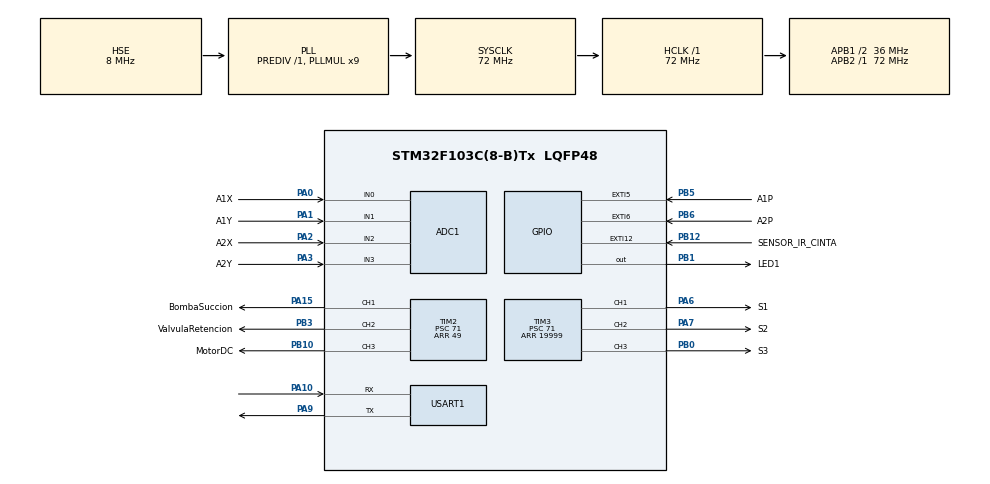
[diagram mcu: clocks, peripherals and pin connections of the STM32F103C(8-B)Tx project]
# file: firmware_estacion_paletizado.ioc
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ADC1.Channel-0\#ChannelRegularConversion=ADC_CHANNEL_0
ADC1.Channel-1\#ChannelRegularConversion=ADC_CHANNEL_1
ADC1.Channel-2\#ChannelRegularConversion=ADC_CHANNEL_2
ADC1.Channel-3\#ChannelRegularConversion=ADC_CHANNEL_3
ADC1.ContinuousConvMode=ENABLE
ADC1.NbrOfConversion=4
ADC1.NbrOfConversionFlag=1
ADC1.Rank-0\#ChannelRegularConversion=1
ADC1.Rank-1\#ChannelRegularConversion=2
ADC1.Rank-2\#ChannelRegularConversion=3
ADC1.Rank-3\#ChannelRegularConversion=4
ADC1.SamplingTime-0\#ChannelRegularConversion=ADC_SAMPLETIME_239CYCLES_5
ADC1.SamplingTime-1\#ChannelRegularConversion=ADC_SAMPLETIME_239CYCLES_5
ADC1.SamplingTime-2\#ChannelRegularConversion=ADC_SAMPLETIME_239CYCLES_5
ADC1.SamplingTime-3\#ChannelRegularConversion=ADC_SAMPLETIME_239CYCLES_5
ADC1.master=1
Dma.ADC1.0.Direction=DMA_PERIPH_TO_MEMORY
Dma.ADC1.0.Instance=DMA1_Channel1
Dma.ADC1.0.MemDataAlignment=DMA_MDATAALIGN_WORD
Dma.ADC1.0.MemInc=DMA_MINC_ENABLE
Dma.ADC1.0.Mode=DMA_CIRCULAR
Dma.ADC1.0.PeriphDataAlignment=DMA_PDATAALIGN_WORD
Dma.ADC1.0.PeriphInc=DMA_PINC_DISABLE
Dma.ADC1.0.Priority=DMA_PRIORITY_LOW
Dma.Request0=ADC1
Dma.Request1=USART1_TX
Dma.USART1_TX.1.Direction=DMA_MEMORY_TO_PERIPH
Dma.USART1_TX.1.Instance=DMA1_Channel4
Dma.USART1_TX.1.MemDataAlignment=DMA_MDATAALIGN_BYTE
Dma.USART1_TX.1.MemInc=DMA_MINC_ENABLE
Dma.USART1_TX.1.Mode=DMA_NORMAL
Dma.USART1_TX.1.PeriphDataAlignment=DMA_PDATAALIGN_BYTE
Dma.USART1_TX.1.PeriphInc=DMA_PINC_DISABLE
Dma.USART1_TX.1.Priority=DMA_PRIORITY_LOW
Mcu.Family=STM32F1
Mcu.Name=STM32F103C(8-B)Tx
Mcu.Package=LQFP48
NVIC.DMA1_Channel1_IRQn=true\:6\:0\:true\:true\:true\:1\:false\:true\:true
NVIC.DMA1_Channel4_IRQn=true\:5\:0\:true\:false\:true\:false\:true\:true
NVIC.EXTI15_10_IRQn=true\:6\:0\:true\:false\:true\:true\:true\:true
NVIC.EXTI9_5_IRQn=true\:14\:0\:true\:false\:true\:true\:true\:true
NVIC.PriorityGroup=NVIC_PRIORITYGROUP_4
NVIC.TIM3_IRQn=true\:1\:0\:true\:true\:true\:2\:true\:true\:true
NVIC.USART1_IRQn=true\:2\:0\:true\:true\:true\:3\:false\:true\:true
PA0-WKUP.GPIO_Label=A1X
PA0-WKUP.Signal=ADCx_IN0
PA1.GPIO_Label=A1Y
PA1.Signal=ADCx_IN1
PA10.Mode=Asynchronous
PA10.Signal=USART1_RX
PA13.Mode=Serial_Wire
PA13.Signal=SYS_JTMS-SWDIO
PA14.Mode=Serial_Wire
PA14.Signal=SYS_JTCK-SWCLK
PA15.GPIO_Label=BombaSuccion
PA15.GPIO_Speed=GPIO_SPEED_FREQ_HIGH
PA15.Signal=S_TIM2_CH1_ETR
PA2.GPIO_Label=A2X
PA2.Signal=ADCx_IN2
PA3.GPIO_Label=A2Y
PA3.Signal=ADCx_IN3
PA6.GPIO_Label=S1
PA6.Signal=S_TIM3_CH1
PA7.GPIO_Label=S2
PA7.Signal=S_TIM3_CH2
PA9.Mode=Asynchronous
PA9.Signal=USART1_TX
PB0.GPIO_Label=S3
PB0.Signal=S_TIM3_CH3
PB1.GPIO_Label=LED1
PB1.Signal=GPIO_Output
PB10.GPIO_Label=MotorDC
PB10.GPIO_Speed=GPIO_SPEED_FREQ_HIGH
PB10.Signal=S_TIM2_CH3
PB12.GPIO_Label=SENSOR_IR_CINTA
PB12.GPIO_ModeDefaultEXTI=GPIO_MODE_IT_RISING_FALLING
PB12.GPIO_PuPd=GPIO_PULLUP
PB12.Signal=GPXTI12
PB3.GPIO_Label=ValvulaRetencion
PB3.GPIO_Speed=GPIO_SPEED_FREQ_HIGH
PB3.Signal=S_TIM2_CH2
PB5.GPIO_Label=A1P
PB5.GPIO_ModeDefaultEXTI=GPIO_MODE_IT_FALLING
PB5.GPIO_PuPd=GPIO_PULLUP
PB5.Signal=GPXTI5
PB6.GPIO_Label=A2P
PB6.GPIO_ModeDefaultEXTI=GPIO_MODE_IT_FALLING
PB6.GPIO_PuPd=GPIO_PULLUP
PB6.Signal=GPXTI6
PD0-OSC_IN.Mode=HSE-External-Oscillator
PD0-OSC_IN.Signal=RCC_OSC_IN
PD1-OSC_OUT.Mode=HSE-External-Oscillator
PD1-OSC_OUT.Signal=RCC_OSC_OUT
ProjectManager.HeapSize=0x200
ProjectManager.StackSize=0x400
ProjectManager.TargetToolchain=STM32CubeIDE
RCC.ADCPresc=RCC_ADCPCLK2_DIV6
RCC.AHBFreq_Value=72000000
RCC.APB1CLKDivider=RCC_HCLK_DIV2
RCC.APB1Freq_Value=36000000
RCC.APB1TimFreq_Value=72000000
RCC.APB2Freq_Value=72000000
RCC.APB2TimFreq_Value=72000000
RCC.HCLKFreq_Value=72000000
RCC.PLLMUL=RCC_PLL_MUL9
RCC.PLLSourceVirtual=RCC_PLLSOURCE_HSE
RCC.SYSCLKFreq_VALUE=72000000
RCC.SYSCLKSource=RCC_SYSCLKSOURCE_PLLCLK
RCC.USBFreq_Value=72000000
SH.ADCx_IN0.0=ADC1_IN0,IN0
SH.ADCx_IN1.0=ADC1_IN1,IN1
SH.ADCx_IN2.0=ADC1_IN2,IN2
SH.ADCx_IN3.0=ADC1_IN3,IN3
SH.S_TIM2_CH1_ETR.0=TIM2_CH1,PWM Generation1 CH1
SH.S_TIM2_CH2.0=TIM2_CH2,PWM Generation2 CH2
SH.S_TIM2_CH3.0=TIM2_CH3,PWM Generation3 CH3
SH.S_TIM3_CH1.0=TIM3_CH1,PWM Generation1 CH1
SH.S_TIM3_CH2.0=TIM3_CH2,PWM Generation2 CH2
SH.S_TIM3_CH3.0=TIM3_CH3,PWM Generation3 CH3
TIM2.Channel-PWM\ Generation1\ CH1=TIM_CHANNEL_1
TIM2.Channel-PWM\ Generation2\ CH2=TIM_CHANNEL_2
TIM2.Channel-PWM\ Generation3\ CH3=TIM_CHANNEL_3
TIM2.Period=49
TIM2.Prescaler=71
TIM3.AutoReloadPreload=TIM_AUTORELOAD_PRELOAD_DISABLE
TIM3.Channel-PWM\ Generation1\ CH1=TIM_CHANNEL_1
TIM3.Channel-PWM\ Generation2\ CH2=TIM_CHANNEL_2
TIM3.Channel-PWM\ Generation3\ CH3=TIM_CHANNEL_3
TIM3.Period=19999
TIM3.Prescaler=71
TIM3.Pulse-PWM\ Generation1\ CH1=1500
TIM3.Pulse-PWM\ Generation2\ CH2=1500
TIM3.Pulse-PWM\ Generation3\ CH3=1500
USART1.VirtualMode=VM_ASYNC
VP_TIM2_VS_ClockSourceINT.Mode=Internal
VP_TIM3_VS_ClockSourceINT.Mode=Internal
board=custom

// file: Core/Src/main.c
/* USER CODE BEGIN Header */
/**
  ******************************************************************************
  * @file           : main.c
  * @brief          : Main program body
  ******************************************************************************
  * @attention
  *
  * Copyright (c) 2026 STMicroelectronics.
  * All rights reserved.
  *
  * This software is licensed under terms that can be found in the LICENSE file
  * in the root directory of this software component.
  * If no LICENSE file comes with this software, it is provided AS-IS.
  *
  ******************************************************************************
  */
/* USER CODE END Header */
#include "main.h"

/* USER CODE BEGIN Includes */
#include "main_cpp.hpp"
/* USER CODE END Includes */

ADC_HandleTypeDef hadc1;
DMA_HandleTypeDef hdma_adc1;

TIM_HandleTypeDef htim2;
TIM_HandleTypeDef htim3;

UART_HandleTypeDef huart1;
DMA_HandleTypeDef hdma_usart1_tx;

void SystemClock_Config(void);
static void MX_GPIO_Init(void);
static void MX_DMA_Init(void);
static void MX_ADC1_Init(void);
static void MX_TIM3_Init(void);
static void MX_USART1_UART_Init(void);
static void MX_TIM2_Init(void);
static void MX_NVIC_Init(void);

int main(void)
{

  /* MCU Configuration--------------------------------------------------------*/

  /* Reset of all peripherals, Initializes the Flash interface and the Systick. */
  HAL_Init();

  /* Configure the system clock */
  SystemClock_Config();

  /* Initialize all configured peripherals */
  MX_GPIO_Init();
  MX_DMA_Init();
  MX_ADC1_Init();
  MX_TIM3_Init();
  MX_USART1_UART_Init();
  MX_TIM2_Init();

  /* Initialize interrupts */
  MX_NVIC_Init();
  /* USER CODE BEGIN 2 */
  Cpp_Main_Init();
  /* USER CODE END 2 */

  /* Infinite loop */
  while (1)
  {

    /* USER CODE BEGIN 3 */
	  Cpp_Main_Loop();
  }
  /* USER CODE END 3 */
}

void SystemClock_Config(void)
{
  RCC_OscInitTypeDef RCC_OscInitStruct = {0};
  RCC_ClkInitTypeDef RCC_ClkInitStruct = {0};
  RCC_PeriphCLKInitTypeDef PeriphClkInit = {0};

  /** Initializes the RCC Oscillators according to the specified parameters
  * in the RCC_OscInitTypeDef structure.
  */
  RCC_OscInitStruct.OscillatorType = RCC_OSCILLATORTYPE_HSE;
  RCC_OscInitStruct.HSEState = RCC_HSE_ON;
  RCC_OscInitStruct.HSEPredivValue = RCC_HSE_PREDIV_DIV1;
  RCC_OscInitStruct.HSIState = RCC_HSI_ON;
  RCC_OscInitStruct.PLL.PLLState = RCC_PLL_ON;
  RCC_OscInitStruct.PLL.PLLSource = RCC_PLLSOURCE_HSE;
  RCC_OscInitStruct.PLL.PLLMUL = RCC_PLL_MUL9;
  if (HAL_RCC_OscConfig(&RCC_OscInitStruct) != HAL_OK)
  {
    Error_Handler();
  }

  /** Initializes the CPU, AHB and APB buses clocks
  */
  RCC_ClkInitStruct.ClockType = RCC_CLOCKTYPE_HCLK|RCC_CLOCKTYPE_SYSCLK
                              |RCC_CLOCKTYPE_PCLK1|RCC_CLOCKTYPE_PCLK2;
  RCC_ClkInitStruct.SYSCLKSource = RCC_SYSCLKSOURCE_PLLCLK;
  RCC_ClkInitStruct.AHBCLKDivider = RCC_SYSCLK_DIV1;
  RCC_ClkInitStruct.APB1CLKDivider = RCC_HCLK_DIV2;
  RCC_ClkInitStruct.APB2CLKDivider = RCC_HCLK_DIV1;

  if (HAL_RCC_ClockConfig(&RCC_ClkInitStruct, FLASH_LATENCY_2) != HAL_OK)
  {
    Error_Handler();
  }
  PeriphClkInit.PeriphClockSelection = RCC_PERIPHCLK_ADC;
  PeriphClkInit.AdcClockSelection = RCC_ADCPCLK2_DIV6;
  if (HAL_RCCEx_PeriphCLKConfig(&PeriphClkInit) != HAL_OK)
  {
    Error_Handler();
  }
}

/**
  * @brief NVIC Configuration.
  * @retval None
  */
static void MX_NVIC_Init(void)
{
  /* DMA1_Channel1_IRQn interrupt configuration */
  HAL_NVIC_SetPriority(DMA1_Channel1_IRQn, 6, 0);
  HAL_NVIC_EnableIRQ(DMA1_Channel1_IRQn);
  /* TIM3_IRQn interrupt configuration */
  HAL_NVIC_SetPriority(TIM3_IRQn, 1, 0);
  HAL_NVIC_EnableIRQ(TIM3_IRQn);
  /* USART1_IRQn interrupt configuration */
  HAL_NVIC_SetPriority(USART1_IRQn, 2, 0);
  HAL_NVIC_EnableIRQ(USART1_IRQn);
}

static void MX_ADC1_Init(void)
{

  ADC_ChannelConfTypeDef sConfig = {0};

  /** Common config
  */
  hadc1.Instance = ADC1;
  hadc1.Init.ScanConvMode = ADC_SCAN_ENABLE;
  hadc1.Init.ContinuousConvMode = ENABLE;
  hadc1.Init.DiscontinuousConvMode = DISABLE;
  hadc1.Init.ExternalTrigConv = ADC_SOFTWARE_START;
  hadc1.Init.DataAlign = ADC_DATAALIGN_RIGHT;
  hadc1.Init.NbrOfConversion = 4;
  if (HAL_ADC_Init(&hadc1) != HAL_OK)
  {
    Error_Handler();
  }

  /** Configure Regular Channel
  */
  sConfig.Channel = ADC_CHANNEL_0;
  sConfig.Rank = ADC_REGULAR_RANK_1;
  sConfig.SamplingTime = ADC_SAMPLETIME_239CYCLES_5;
  if (HAL_ADC_ConfigChannel(&hadc1, &sConfig) != HAL_OK)
  {
    Error_Handler();
  }

  /** Configure Regular Channel
  */
  sConfig.Channel = ADC_CHANNEL_1;
  sConfig.Rank = ADC_REGULAR_RANK_2;
  if (HAL_ADC_ConfigChannel(&hadc1, &sConfig) != HAL_OK)
  {
    Error_Handler();
  }

  /** Configure Regular Channel
  */
  sConfig.Channel = ADC_CHANNEL_2;
  sConfig.Rank = ADC_REGULAR_RANK_3;
  if (HAL_ADC_ConfigChannel(&hadc1, &sConfig) != HAL_OK)
  {
    Error_Handler();
  }

  /** Configure Regular Channel
  */
  sConfig.Channel = ADC_CHANNEL_3;
  sConfig.Rank = ADC_REGULAR_RANK_4;
  if (HAL_ADC_ConfigChannel(&hadc1, &sConfig) != HAL_OK)
  {
    Error_Handler();
  }

}

static void MX_TIM2_Init(void)
{

  TIM_ClockConfigTypeDef sClockSourceConfig = {0};
  TIM_MasterConfigTypeDef sMasterConfig = {0};
  TIM_OC_InitTypeDef sConfigOC = {0};

  htim2.Instance = TIM2;
  htim2.Init.Prescaler = 71;
  htim2.Init.CounterMode = TIM_COUNTERMODE_UP;
  htim2.Init.Period = 49;
  htim2.Init.ClockDivision = TIM_CLOCKDIVISION_DIV1;
  htim2.Init.AutoReloadPreload = TIM_AUTORELOAD_PRELOAD_DISABLE;
  if (HAL_TIM_Base_Init(&htim2) != HAL_OK)
  {
    Error_Handler();
  }
  sClockSourceConfig.ClockSource = TIM_CLOCKSOURCE_INTERNAL;
  if (HAL_TIM_ConfigClockSource(&htim2, &sClockSourceConfig) != HAL_OK)
  {
    Error_Handler();
  }
  if (HAL_TIM_PWM_Init(&htim2) != HAL_OK)
  {
    Error_Handler();
  }
  sMasterConfig.MasterOutputTrigger = TIM_TRGO_RESET;
  sMasterConfig.MasterSlaveMode = TIM_MASTERSLAVEMODE_DISABLE;
  if (HAL_TIMEx_MasterConfigSynchronization(&htim2, &sMasterConfig) != HAL_OK)
  {
    Error_Handler();
  }
  sConfigOC.OCMode = TIM_OCMODE_PWM1;
  sConfigOC.Pulse = 0;
  sConfigOC.OCPolarity = TIM_OCPOLARITY_HIGH;
  sConfigOC.OCFastMode = TIM_OCFAST_DISABLE;
  if (HAL_TIM_PWM_ConfigChannel(&htim2, &sConfigOC, TIM_CHANNEL_1) != HAL_OK)
  {
    Error_Handler();
  }
  if (HAL_TIM_PWM_ConfigChannel(&htim2, &sConfigOC, TIM_CHANNEL_2) != HAL_OK)
  {
    Error_Handler();
  }
  if (HAL_TIM_PWM_ConfigChannel(&htim2, &sConfigOC, TIM_CHANNEL_3) != HAL_OK)
  {
    Error_Handler();
  }
  HAL_TIM_MspPostInit(&htim2);

}

static void MX_TIM3_Init(void)
{

  TIM_ClockConfigTypeDef sClockSourceConfig = {0};
  TIM_MasterConfigTypeDef sMasterConfig = {0};
  TIM_OC_InitTypeDef sConfigOC = {0};

  htim3.Instance = TIM3;
  htim3.Init.Prescaler = 71;
  htim3.Init.CounterMode = TIM_COUNTERMODE_UP;
  htim3.Init.Period = 19999;
  htim3.Init.ClockDivision = TIM_CLOCKDIVISION_DIV1;
  htim3.Init.AutoReloadPreload = TIM_AUTORELOAD_PRELOAD_DISABLE;
  if (HAL_TIM_Base_Init(&htim3) != HAL_OK)
  {
    Error_Handler();
  }
  sClockSourceConfig.ClockSource = TIM_CLOCKSOURCE_INTERNAL;
  if (HAL_TIM_ConfigClockSource(&htim3, &sClockSourceConfig) != HAL_OK)
  {
    Error_Handler();
  }
  if (HAL_TIM_PWM_Init(&htim3) != HAL_OK)
  {
    Error_Handler();
  }
  sMasterConfig.MasterOutputTrigger = TIM_TRGO_RESET;
  sMasterConfig.MasterSlaveMode = TIM_MASTERSLAVEMODE_DISABLE;
  if (HAL_TIMEx_MasterConfigSynchronization(&htim3, &sMasterConfig) != HAL_OK)
  {
    Error_Handler();
  }
  sConfigOC.OCMode = TIM_OCMODE_PWM1;
  sConfigOC.Pulse = 1500;
  sConfigOC.OCPolarity = TIM_OCPOLARITY_HIGH;
  sConfigOC.OCFastMode = TIM_OCFAST_DISABLE;
  if (HAL_TIM_PWM_ConfigChannel(&htim3, &sConfigOC, TIM_CHANNEL_1) != HAL_OK)
  {
    Error_Handler();
  }
  if (HAL_TIM_PWM_ConfigChannel(&htim3, &sConfigOC, TIM_CHANNEL_2) != HAL_OK)
  {
    Error_Handler();
  }
  if (HAL_TIM_PWM_ConfigChannel(&htim3, &sConfigOC, TIM_CHANNEL_3) != HAL_OK)
  {
    Error_Handler();
  }
  HAL_TIM_MspPostInit(&htim3);

}

static void MX_USART1_UART_Init(void)
{

  huart1.Instance = USART1;
  huart1.Init.BaudRate = 115200;
  huart1.Init.WordLength = UART_WORDLENGTH_8B;
  huart1.Init.StopBits = UART_STOPBITS_1;
  huart1.Init.Parity = UART_PARITY_NONE;
  huart1.Init.Mode = UART_MODE_TX_RX;
  huart1.Init.HwFlowCtl = UART_HWCONTROL_NONE;
  huart1.Init.OverSampling = UART_OVERSAMPLING_16;
  if (HAL_UART_Init(&huart1) != HAL_OK)
  {
    Error_Handler();
  }

}

static void MX_DMA_Init(void)
{

  /* DMA controller clock enable */
  __HAL_RCC_DMA1_CLK_ENABLE();

  /* DMA interrupt init */
  /* DMA1_Channel4_IRQn interrupt configuration */
  HAL_NVIC_SetPriority(DMA1_Channel4_IRQn, 5, 0);
  HAL_NVIC_EnableIRQ(DMA1_Channel4_IRQn);

}

static void MX_GPIO_Init(void)
{
  GPIO_InitTypeDef GPIO_InitStruct = {0};

  /* GPIO Ports Clock Enable */
  __HAL_RCC_GPIOD_CLK_ENABLE();
  __HAL_RCC_GPIOA_CLK_ENABLE();
  __HAL_RCC_GPIOB_CLK_ENABLE();

  /*Configure GPIO pin Output Level */
  HAL_GPIO_WritePin(LED1_GPIO_Port, LED1_Pin, GPIO_PIN_RESET);

  /*Configure GPIO pin : LED1_Pin */
  GPIO_InitStruct.Pin = LED1_Pin;
  GPIO_InitStruct.Mode = GPIO_MODE_OUTPUT_PP;
  GPIO_InitStruct.Pull = GPIO_NOPULL;
  GPIO_InitStruct.Speed = GPIO_SPEED_FREQ_LOW;
  HAL_GPIO_Init(LED1_GPIO_Port, &GPIO_InitStruct);

  /*Configure GPIO pin : SENSOR_IR_CINTA_Pin */
  GPIO_InitStruct.Pin = SENSOR_IR_CINTA_Pin;
  GPIO_InitStruct.Mode = GPIO_MODE_IT_RISING_FALLING;
  GPIO_InitStruct.Pull = GPIO_PULLUP;
  HAL_GPIO_Init(SENSOR_IR_CINTA_GPIO_Port, &GPIO_InitStruct);

  /*Configure GPIO pins : A1P_Pin A2P_Pin */
  GPIO_InitStruct.Pin = A1P_Pin|A2P_Pin;
  GPIO_InitStruct.Mode = GPIO_MODE_IT_FALLING;
  GPIO_InitStruct.Pull = GPIO_PULLUP;
  HAL_GPIO_Init(GPIOB, &GPIO_InitStruct);

  /* EXTI interrupt init*/
  HAL_NVIC_SetPriority(EXTI9_5_IRQn, 14, 0);
  HAL_NVIC_EnableIRQ(EXTI9_5_IRQn);

  HAL_NVIC_SetPriority(EXTI15_10_IRQn, 6, 0);
  HAL_NVIC_EnableIRQ(EXTI15_10_IRQn);

}

void Error_Handler(void)
{
  /* USER CODE BEGIN Error_Handler_Debug */
  /* User can add his own implementation to report the HAL error return state */
  /* Error irrecuperable: cortar la potencia de bomba (CH1), valvula (CH2) y cinta (CH3), que
   * de otro modo seguirian con el ultimo PWM. Los servos (TIM3) sostienen la posicion. */
  TIM2->CCR1 = 0U;
  TIM2->CCR2 = 0U;
  TIM2->CCR3 = 0U;
  __disable_irq();
  while (1)
  {
  }
  /* USER CODE END Error_Handler_Debug */
}
